# Air001xx_DFP register map
Vendor: AirM2M; Series: Air001; File version: 1.0.0
CPU: CM0+ r0p1, little endian, no MPU, no FPU, 4 interrupt priority bits
Registers are 32-bit, read-write, reset 0x0 unless marked. A register's access mark holds for its fields unless they carry their own. Offsets are from the block's base; [hi:lo] are bit positions; {n}, {i} and the like mark numbered series; 'fields as' and 'values as' point back to an identical list.

## SYSCFG — System configuration controller
Base 0x40010000
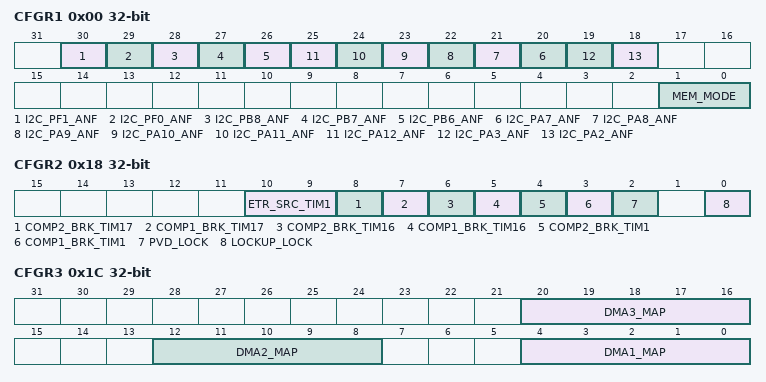
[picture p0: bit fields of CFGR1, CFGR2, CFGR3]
0x00 CFGR1 — SYSCFG configuration register 1
  [30] I2C_PF1_ANF — Analog filter enable control driving capability activation bits PF1
  [29] I2C_PF0_ANF — Analog filter enable control driving capability activation bits PF0
  [28] I2C_PB8_ANF — Analog filter enable control driving capability activation bits PB8
  [27] I2C_PB7_ANF — Analog filter enable control driving capability activation bits PB7
  [26] I2C_PB6_ANF — Analog filter enable control driving capability activation bits PB6
  [n+13] I2C_PA{n}_ANF (n=7..12) — Analog filter enable control driving capability activation bits PA{n}
  [19] I2C_PA3_ANF — Analog filter enable control driving capability activation bits PA3
  [18] I2C_PA2_ANF — Analog filter enable control driving capability activation bits PA2
  [1:0] MEM_MODE — Memory mapping selection bits
0x18 CFGR2 — SYSCFG configuration register 2
  [10:9] ETR_SRC_TIM1 — TIM1 ETR source selection
  [8] COMP2_BRK_TIM17 — COMP2 is enable to input of TIM17 break
  [7] COMP1_BRK_TIM17 — COMP1 is enable to input of TIM17 break
  [6] COMP2_BRK_TIM16 — COMP2 is enable to input of TIM16 break
  [5] COMP1_BRK_TIM16 — COMP1 is enable to input of TIM16 break
  [4] COMP2_BRK_TIM1 — COMP2 is enable to input of TIM1 break
  [3] COMP1_BRK_TIM1 — COMP1 is enable to input of TIM1 break
  [2] PVD_LOCK — PVD lock enable bit
  [0] LOCKUP_LOCK — Cortex-M0+ LOCKUP bit enable bit
0x1C CFGR3 — SYSCFG configuration register 3
  [20:16] DMA3_MAP — DMA channel3 requeset selection
  [12:8] DMA2_MAP — DMA channel2 requeset selection
  [4:0] DMA1_MAP — DMA channel1 requeset selection

## DMA — Direct memory access
Base 0x40020000
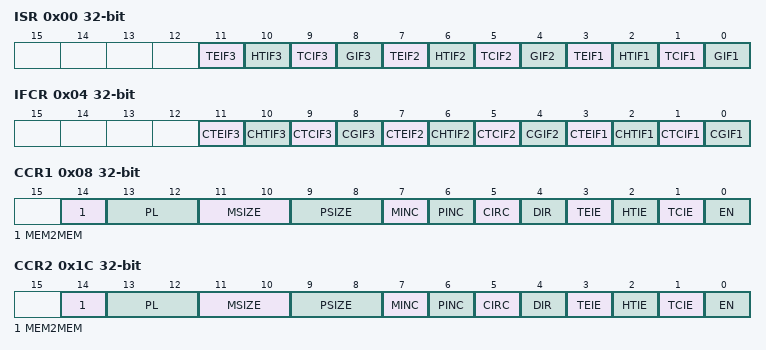
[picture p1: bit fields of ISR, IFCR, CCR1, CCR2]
0x00 ISR ro — DMA interrupt status register (DMA_ISR)
  [11] TEIF3 — Channel 3 Transfer Error flag
  [10] HTIF3 — Channel 3 Half Transfer Complete flag
  [9] TCIF3 — Channel 3 Transfer Complete flag
  [8] GIF3 — Channel 3 Global interrupt flag
  [7] TEIF2 — Channel 2 Transfer Error flag
  [6] HTIF2 — Channel 2 Half Transfer Complete flag
  [5] TCIF2 — Channel 2 Transfer Complete flag
  [4] GIF2 — Channel 2 Global interrupt flag
  [3] TEIF1 — Channel 1 Transfer Error flag
  [2] HTIF1 — Channel 1 Half Transfer Complete flag
  [1] TCIF1 — Channel 1 Transfer Complete flag
  [0] GIF1 — Channel 1 Global interrupt flag
0x04 IFCR wo — DMA interrupt flag clear register (DMA_IFCR)
  [11] CTEIF3 — Channel 3 Transfer Error clear
  [10] CHTIF3 — Channel 3 Half Transfer clear
  [9] CTCIF3 — Channel 3 Transfer Complete clear
  [8] CGIF3 — Channel 3 Global interrupt clear
  [7] CTEIF2 — Channel 2 Transfer Error clear
  [6] CHTIF2 — Channel 2 Half Transfer clear
  [5] CTCIF2 — Channel 2 Transfer Complete clear
  [4] CGIF2 — Channel 2 Global interrupt clear
  [3] CTEIF1 — Channel 1 Transfer Error clear
  [2] CHTIF1 — Channel 1 Half Transfer clear
  [1] CTCIF1 — Channel 1 Transfer Complete clear
  [0] CGIF1 — Channel 1 Global interrupt clear
0x08 CCR1 — DMA channel configuration register (DMA_CCR)
  [14] MEM2MEM — Memory to memory mode
  [13:12] PL — Channel Priority level
  [11:10] MSIZE — Memory size
  [9:8] PSIZE — Peripheral size
  [7] MINC — Memory increment mode
  [6] PINC — Peripheral increment mode
  [5] CIRC — Circular mode
  [4] DIR — Data transfer direction
  [3] TEIE — Transfer error interrupt enable
  [2] HTIE — Half Transfer interrupt enable
  [1] TCIE — Transfer complete interrupt enable
  [0] EN — Channel enable
0x0C CNDTR1 — DMA channel 1 number of data register
  [15:0] NDT — Number of data to transfer
0x10 CPAR1 — DMA channel 1 peripheral address register
  [31:0] PA — Peripheral address
{0x0+0x14*i} CMAR{i} (i=1..3) — DMA channel {i} memory address register
  [31:0] MA — Memory address
0x1C CCR2 — DMA channel configuration register (DMA_CCR)
  fields as CCR1
0x20 CNDTR2 — DMA channel 2 number of data register
  [15:0] NDT — Number of data to transfer
0x24 CPAR2 — DMA channel 2 peripheral address register
  [31:0] PA — Peripheral address
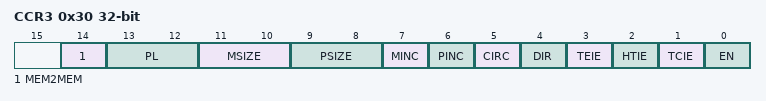
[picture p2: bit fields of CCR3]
0x30 CCR3 — DMA channel configuration register (DMA_CCR)
  fields as CCR1
0x34 CNDTR3 — DMA channel 3 number of data register
  [15:0] NDT — Number of data to transfer
0x38 CPAR3 — DMA channel 3 peripheral address register
  [31:0] PA — Peripheral address
